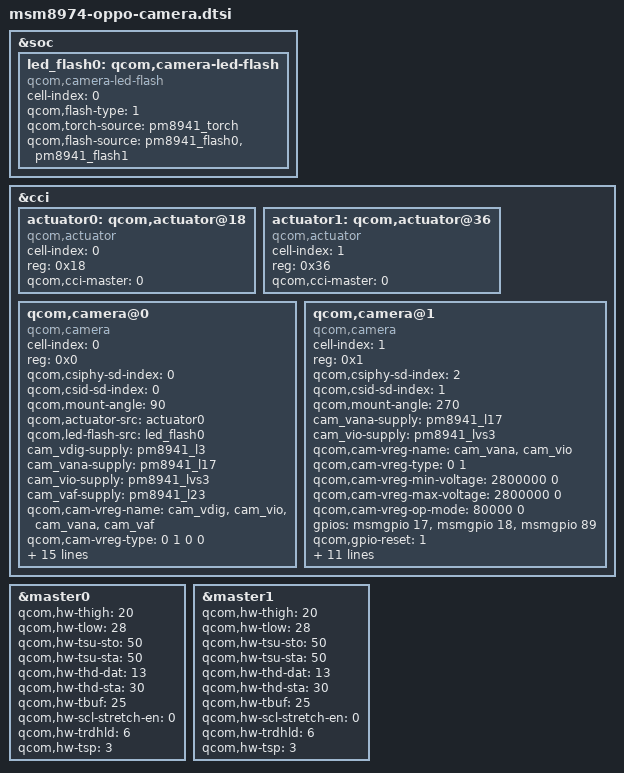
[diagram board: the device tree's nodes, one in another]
/* Copyright (c) 2012-2013, The Linux Foundation. All rights reserved.
 *
 * This program is free software; you can redistribute it and/or modify
 * it under the terms of the GNU General Public License version 2 and
 * only version 2 as published by the Free Software Foundation.
 *
 * This program is distributed in the hope that it will be useful,
 * but WITHOUT ANY WARRANTY; without even the implied warranty of
 * MERCHANTABILITY or FITNESS FOR A PARTICULAR PURPOSE.  See the
 * GNU General Public License for more details.
 */

&soc {
	led_flash0: qcom,camera-led-flash {
		cell-index = <0>;
		compatible = "qcom,camera-led-flash";
		qcom,flash-type = <1>;
		qcom,torch-source = <&pm8941_torch>;
		qcom,flash-source = <&pm8941_flash0 &pm8941_flash1>;
	};
};

&cci {
	actuator0: qcom,actuator@18 {
		cell-index = <0>;
		reg = <0x18>;
		compatible = "qcom,actuator";
		qcom,cci-master = <0>;
	};

	actuator1: qcom,actuator@36 {
		cell-index = <1>;
		reg = <0x36>;
		compatible = "qcom,actuator";
		qcom,cci-master = <0>;
	};

	qcom,camera@0 {
		cell-index = <0>;
		compatible = "qcom,camera";
		reg = <0x0>;
		qcom,csiphy-sd-index = <0>;
		qcom,csid-sd-index = <0>;
		qcom,mount-angle = <90>;
		qcom,actuator-src = <&actuator0>;
		qcom,led-flash-src = <&led_flash0>;
		cam_vdig-supply = <&pm8941_l3>;
		cam_vana-supply = <&pm8941_l17>;
		cam_vio-supply = <&pm8941_lvs3>;
		cam_vaf-supply = <&pm8941_l23>;
		qcom,cam-vreg-name = "cam_vdig", "cam_vio", "cam_vana",
				     "cam_vaf";
		qcom,cam-vreg-type = <0 1 0 0>;
		qcom,cam-vreg-min-voltage = <1000000 0 2800000 2800000>;
		qcom,cam-vreg-max-voltage = <1000000 0 2800000 2800000>;
		qcom,cam-vreg-op-mode = <105000 0 80000 100000>;
		qcom,gpio-no-mux = <0>;
		gpios = <&msmgpio 15 0>,
			<&msmgpio 90 0>;
		qcom,gpio-reset = <1>;
		qcom,gpio-req-tbl-num = <0 1>;
		qcom,gpio-req-tbl-flags = <1 0>;
		qcom,gpio-req-tbl-label = "CAMIF_MCLK0",
					  "CAM_RESET0";
		qcom,sensor-position = <0>;
		qcom,sensor-mode = <0>;
		qcom,cci-master = <0>;
		status = "ok";
	};


	qcom,camera@1 {
		cell-index = <1>;
		compatible = "qcom,camera";
		reg = <0x1>;
		qcom,csiphy-sd-index = <2>;
		qcom,csid-sd-index = <1>;
		qcom,mount-angle = <270>;
		cam_vana-supply = <&pm8941_l17>;
		cam_vio-supply = <&pm8941_lvs3>;
		qcom,cam-vreg-name = "cam_vana", "cam_vio";
		qcom,cam-vreg-type = <0 1>;
		qcom,cam-vreg-min-voltage = <2800000 0>;
		qcom,cam-vreg-max-voltage = <2800000 0>;
		qcom,cam-vreg-op-mode = <80000 0>;
		gpios = <&msmgpio 17 0>,
			<&msmgpio 18 0>,
			<&msmgpio 89 0>;
		qcom,gpio-reset = <1>;
		qcom,gpio-standby = <2>;
		qcom,gpio-req-tbl-num = <0 1 2>;
		qcom,gpio-req-tbl-flags = <1 0 0>;
		qcom,gpio-req-tbl-label = "CAMIF_MCLK",
					  "CAM_RESET1",
					  "CAM_STANDBY";
		qcom,gpio-set-tbl-num = <1 1>;
		qcom,gpio-set-tbl-flags = <0 2>;
		qcom,gpio-set-tbl-delay = <1000 4000>;
		qcom,sensor-position = <1>;
		qcom,sensor-mode = <0>;
		qcom,cci-master = <1>;
		status = "ok";
	};
};

&master0 {
	qcom,hw-thigh = <20>;
	qcom,hw-tlow = <28>;
	qcom,hw-tsu-sto = <50>;
	qcom,hw-tsu-sta = <50>;
	qcom,hw-thd-dat = <13>;
	qcom,hw-thd-sta = <30>;
	qcom,hw-tbuf = <25>;
	qcom,hw-scl-stretch-en = <0>;
	qcom,hw-trdhld = <6>;
	qcom,hw-tsp = <3>;
	status = "ok";
};

&master1 {
	qcom,hw-thigh = <20>;
	qcom,hw-tlow = <28>;
	qcom,hw-tsu-sto = <50>;
	qcom,hw-tsu-sta = <50>;
	qcom,hw-thd-dat = <13>;
	qcom,hw-thd-sta = <30>;
	qcom,hw-tbuf = <25>;
	qcom,hw-scl-stretch-en = <0>;
	qcom,hw-trdhld = <6>;
	qcom,hw-tsp = <3>;
	status = "ok";
};
